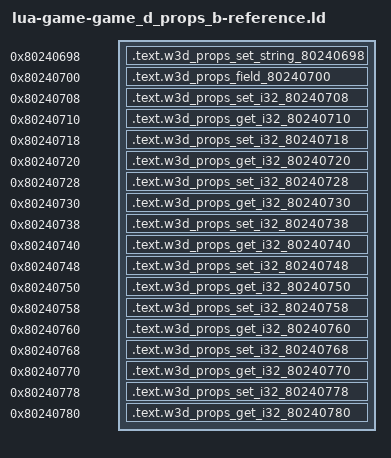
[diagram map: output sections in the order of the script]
/* Generated reference-only placements. All bodies are source-built. */
OUTPUT_FORMAT("elf32-powerpc")
OUTPUT_ARCH(powerpc)
ENTRY(w3d_props_set_string_80240698)
_SDA_BASE_ = 0x804b2540;
_SDA2_BASE_ = 0x804c2540;
w3d_string_release_header = 0x8020bb2c;
SECTIONS {
  .text.w3d_props_set_string_80240698 0x80240698 : { *(.text.w3d_props_set_string_80240698) }
  .text.w3d_props_field_80240700 0x80240700 : { *(.text.w3d_props_field_80240700) }
  .text.w3d_props_set_i32_80240708 0x80240708 : { *(.text.w3d_props_set_i32_80240708) }
  .text.w3d_props_get_i32_80240710 0x80240710 : { *(.text.w3d_props_get_i32_80240710) }
  .text.w3d_props_set_i32_80240718 0x80240718 : { *(.text.w3d_props_set_i32_80240718) }
  .text.w3d_props_get_i32_80240720 0x80240720 : { *(.text.w3d_props_get_i32_80240720) }
  .text.w3d_props_set_i32_80240728 0x80240728 : { *(.text.w3d_props_set_i32_80240728) }
  .text.w3d_props_get_i32_80240730 0x80240730 : { *(.text.w3d_props_get_i32_80240730) }
  .text.w3d_props_set_i32_80240738 0x80240738 : { *(.text.w3d_props_set_i32_80240738) }
  .text.w3d_props_get_i32_80240740 0x80240740 : { *(.text.w3d_props_get_i32_80240740) }
  .text.w3d_props_set_i32_80240748 0x80240748 : { *(.text.w3d_props_set_i32_80240748) }
  .text.w3d_props_get_i32_80240750 0x80240750 : { *(.text.w3d_props_get_i32_80240750) }
  .text.w3d_props_set_i32_80240758 0x80240758 : { *(.text.w3d_props_set_i32_80240758) }
  .text.w3d_props_get_i32_80240760 0x80240760 : { *(.text.w3d_props_get_i32_80240760) }
  .text.w3d_props_set_i32_80240768 0x80240768 : { *(.text.w3d_props_set_i32_80240768) }
  .text.w3d_props_get_i32_80240770 0x80240770 : { *(.text.w3d_props_get_i32_80240770) }
  .text.w3d_props_set_i32_80240778 0x80240778 : { *(.text.w3d_props_set_i32_80240778) }
  .text.w3d_props_get_i32_80240780 0x80240780 : { *(.text.w3d_props_get_i32_80240780) }
  /DISCARD/ : { *(.text*) *(.rodata*) *(.data*) *(.bss*) *(.sdata*) *(.sbss*) *(.comment) }
}
